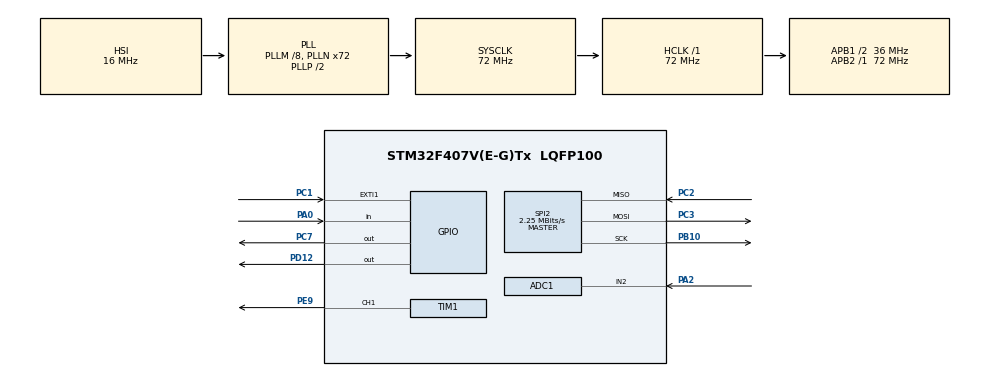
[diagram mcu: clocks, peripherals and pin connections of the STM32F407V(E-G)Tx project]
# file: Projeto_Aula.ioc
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ADC1.Channel-1\#ChannelRegularConversion=ADC_CHANNEL_2
ADC1.ContinuousConvMode=ENABLE
ADC1.NbrOfConversion=1
ADC1.NbrOfConversionFlag=1
ADC1.Rank-1\#ChannelRegularConversion=1
ADC1.SamplingTime-1\#ChannelRegularConversion=ADC_SAMPLETIME_3CYCLES
ADC1.master=1
Mcu.Family=STM32F4
Mcu.Name=STM32F407V(E-G)Tx
Mcu.Package=LQFP100
NVIC.EXTI1_IRQn=true\:0\:0\:false\:false\:true\:true\:true\:true
NVIC.PriorityGroup=NVIC_PRIORITYGROUP_4
PA0-WKUP.Signal=GPIO_Input
PA13.Mode=Serial_Wire
PA13.Signal=SYS_JTMS-SWDIO
PA14.Mode=Serial_Wire
PA14.Signal=SYS_JTCK-SWCLK
PA2.Signal=ADCx_IN2
PB10.Mode=Full_Duplex_Master
PB10.Signal=SPI2_SCK
PC1.GPIO_ModeDefaultEXTI=GPIO_MODE_IT_RISING
PC1.GPIO_PuPd=GPIO_PULLDOWN
PC1.Signal=GPXTI1
PC2.Mode=Full_Duplex_Master
PC2.Signal=SPI2_MISO
PC3.Mode=Full_Duplex_Master
PC3.Signal=SPI2_MOSI
PC7.Signal=GPIO_Output
PD12.Signal=GPIO_Output
PE9.Signal=S_TIM1_CH1
PH0-OSC_IN.Mode=HSE-External-Oscillator
PH0-OSC_IN.Signal=RCC_OSC_IN
PH1-OSC_OUT.Mode=HSE-External-Oscillator
PH1-OSC_OUT.Signal=RCC_OSC_OUT
ProjectManager.HeapSize=0x200
ProjectManager.StackSize=0x400
ProjectManager.TargetToolchain=STM32CubeIDE
RCC.48MHZClocksFreq_Value=36000000
RCC.AHBFreq_Value=72000000
RCC.APB1CLKDivider=RCC_HCLK_DIV2
RCC.APB1Freq_Value=36000000
RCC.APB1TimFreq_Value=72000000
RCC.APB2Freq_Value=72000000
RCC.APB2TimFreq_Value=72000000
RCC.CortexFreq_Value=72000000
RCC.HCLKFreq_Value=72000000
RCC.HSE_VALUE=8000000
RCC.HSI_VALUE=16000000
RCC.LSE_VALUE=32768
RCC.PLLM=8
RCC.PLLN=72
RCC.SYSCLKFreq_VALUE=72000000
RCC.SYSCLKSource=RCC_SYSCLKSOURCE_PLLCLK
RCC.VCOOutputFreq_Value=144000000
SH.ADCx_IN2.0=ADC1_IN2,IN2
SH.S_TIM1_CH1.0=TIM1_CH1,PWM Generation1 CH1
SPI2.BaudRatePrescaler=SPI_BAUDRATEPRESCALER_16
SPI2.CalculateBaudRate=2.25 MBits/s
SPI2.Direction=SPI_DIRECTION_2LINES
SPI2.Mode=SPI_MODE_MASTER
SPI2.VirtualType=VM_MASTER
TIM1.AutoReloadPreload=TIM_AUTORELOAD_PRELOAD_ENABLE
TIM1.Channel-PWM\ Generation1\ CH1=TIM_CHANNEL_1
TIM1.Period=100
TIM1.Prescaler=719
TIM1.Pulse-PWM\ Generation1\ CH1=80
VP_TIM1_VS_ClockSourceINT.Mode=Internal
board=custom

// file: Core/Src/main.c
/* USER CODE BEGIN Header */
/**
  ******************************************************************************
  * @file           : main.c
  * @brief          : Main program body
  ******************************************************************************
  * @attention
  *
  * Copyright (c) 2024 STMicroelectronics.
  * All rights reserved.
  *
  * This software is licensed under terms that can be found in the LICENSE file
  * in the root directory of this software component.
  * If no LICENSE file comes with this software, it is provided AS-IS.
  *
  ******************************************************************************
  */
/* USER CODE END Header */
#include "main.h"

ADC_HandleTypeDef hadc1;

SPI_HandleTypeDef hspi2;

TIM_HandleTypeDef htim1;

void SystemClock_Config(void);
static void MX_GPIO_Init(void);
static void MX_ADC1_Init(void);
static void MX_TIM1_Init(void);
static void MX_SPI2_Init(void);
/* USER CODE BEGIN PFP */
uint16_t adc_read;
uint8_t *buffer = "SEJAM BEM VINDOS A ENGENHARIA ELETRONICA!";
//uint8_t value = 0b10101010;

/* USER CODE END PFP */

int main(void)
{

  /* MCU Configuration--------------------------------------------------------*/

  /* Reset of all peripherals, Initializes the Flash interface and the Systick. */
  HAL_Init();

  /* Configure the system clock */
  SystemClock_Config();

  /* Initialize all configured peripherals */
  MX_GPIO_Init();
  MX_ADC1_Init();
  MX_TIM1_Init();
  MX_SPI2_Init();
  /* USER CODE BEGIN 2 */
  HAL_TIM_PWM_Start(&htim1, TIM_CHANNEL_1);

  /* USER CODE END 2 */

  /* Infinite loop */
  /* USER CODE BEGIN WHILE */
  while (1)
  {

// GPIO OUTPUT -- EXAMPLE
/*
	  while(1){ // HAL -> HARDWARE ABSTRACTION LAYER
		HAL_GPIO_WritePin(GPIOD, GPIO_PIN_12,1);
		HAL_Delay(1000);
		HAL_GPIO_WritePin(GPIOD, GPIO_PIN_12,0);
		HAL_Delay(1000);
	 }
*/

// GPIO INPUT(POLLING) -- EXAMPLE
/*

	  while(1){
		if(HAL_GPIO_ReadPin(GPIOA, GPIO_PIN_0)){
			HAL_GPIO_WritePin(GPIOD, GPIO_PIN_12,1);
		}else{
			HAL_GPIO_WritePin(GPIOD, GPIO_PIN_12,0);
		}
	 }
*/

// ADC(POLLING) -- EXAMPLE

/*

	  while(1){
		  HAL_ADC_Start(&hadc1);
		  HAL_ADC_PollForConversion(&hadc1, 500);
		  adc_read = HAL_ADC_GetValue(&hadc1);
		  HAL_ADC_Stop(&hadc1);
	 }
*/

// TIMER PWM GENERATION -- EXAMPLE

/*
	  while(1){
		TIM1->CCR1 = 80;
		HAL_Delay(5000);
		TIM1->CCR1 = 40;
		HAL_Delay(5000);
	  }
*/

// SPI PROTOCOL SIGNAL GENERATION -- EXAMPLE

	  while(1){
		  HAL_GPIO_WritePin(GPIOC, GPIO_PIN_7,0);
		  HAL_SPI_Transmit(&hspi2,(uint8_t *)buffer,60, 10);
		  HAL_GPIO_WritePin(GPIOC, GPIO_PIN_7,1);
		  HAL_Delay(1000);
	  }

    /* USER CODE END WHILE */

  }
}

void SystemClock_Config(void)
{
  RCC_OscInitTypeDef RCC_OscInitStruct = {0};
  RCC_ClkInitTypeDef RCC_ClkInitStruct = {0};

  /** Configure the main internal regulator output voltage
  */
  __HAL_RCC_PWR_CLK_ENABLE();
  __HAL_PWR_VOLTAGESCALING_CONFIG(PWR_REGULATOR_VOLTAGE_SCALE1);

  /** Initializes the RCC Oscillators according to the specified parameters
  * in the RCC_OscInitTypeDef structure.
  */
  RCC_OscInitStruct.OscillatorType = RCC_OSCILLATORTYPE_HSI;
  RCC_OscInitStruct.HSIState = RCC_HSI_ON;
  RCC_OscInitStruct.HSICalibrationValue = RCC_HSICALIBRATION_DEFAULT;
  RCC_OscInitStruct.PLL.PLLState = RCC_PLL_ON;
  RCC_OscInitStruct.PLL.PLLSource = RCC_PLLSOURCE_HSI;
  RCC_OscInitStruct.PLL.PLLM = 8;
  RCC_OscInitStruct.PLL.PLLN = 72;
  RCC_OscInitStruct.PLL.PLLP = RCC_PLLP_DIV2;
  RCC_OscInitStruct.PLL.PLLQ = 4;
  if (HAL_RCC_OscConfig(&RCC_OscInitStruct) != HAL_OK)
  {
    Error_Handler();
  }

  /** Initializes the CPU, AHB and APB buses clocks
  */
  RCC_ClkInitStruct.ClockType = RCC_CLOCKTYPE_HCLK|RCC_CLOCKTYPE_SYSCLK
                              |RCC_CLOCKTYPE_PCLK1|RCC_CLOCKTYPE_PCLK2;
  RCC_ClkInitStruct.SYSCLKSource = RCC_SYSCLKSOURCE_PLLCLK;
  RCC_ClkInitStruct.AHBCLKDivider = RCC_SYSCLK_DIV1;
  RCC_ClkInitStruct.APB1CLKDivider = RCC_HCLK_DIV2;
  RCC_ClkInitStruct.APB2CLKDivider = RCC_HCLK_DIV1;

  if (HAL_RCC_ClockConfig(&RCC_ClkInitStruct, FLASH_LATENCY_2) != HAL_OK)
  {
    Error_Handler();
  }
}

static void MX_ADC1_Init(void)
{

  ADC_ChannelConfTypeDef sConfig = {0};

  /** Configure the global features of the ADC (Clock, Resolution, Data Alignment and number of conversion)
  */
  hadc1.Instance = ADC1;
  hadc1.Init.ClockPrescaler = ADC_CLOCK_SYNC_PCLK_DIV2;
  hadc1.Init.Resolution = ADC_RESOLUTION_12B;
  hadc1.Init.ScanConvMode = DISABLE;
  hadc1.Init.ContinuousConvMode = ENABLE;
  hadc1.Init.DiscontinuousConvMode = DISABLE;
  hadc1.Init.ExternalTrigConvEdge = ADC_EXTERNALTRIGCONVEDGE_NONE;
  hadc1.Init.ExternalTrigConv = ADC_SOFTWARE_START;
  hadc1.Init.DataAlign = ADC_DATAALIGN_RIGHT;
  hadc1.Init.NbrOfConversion = 1;
  hadc1.Init.DMAContinuousRequests = DISABLE;
  hadc1.Init.EOCSelection = ADC_EOC_SINGLE_CONV;
  if (HAL_ADC_Init(&hadc1) != HAL_OK)
  {
    Error_Handler();
  }

  /** Configure for the selected ADC regular channel its corresponding rank in the sequencer and its sample time.
  */
  sConfig.Channel = ADC_CHANNEL_2;
  sConfig.Rank = 1;
  sConfig.SamplingTime = ADC_SAMPLETIME_3CYCLES;
  if (HAL_ADC_ConfigChannel(&hadc1, &sConfig) != HAL_OK)
  {
    Error_Handler();
  }

}

static void MX_SPI2_Init(void)
{

  /* SPI2 parameter configuration*/
  hspi2.Instance = SPI2;
  hspi2.Init.Mode = SPI_MODE_MASTER;
  hspi2.Init.Direction = SPI_DIRECTION_2LINES;
  hspi2.Init.DataSize = SPI_DATASIZE_8BIT;
  hspi2.Init.CLKPolarity = SPI_POLARITY_LOW;
  hspi2.Init.CLKPhase = SPI_PHASE_1EDGE;
  hspi2.Init.NSS = SPI_NSS_SOFT;
  hspi2.Init.BaudRatePrescaler = SPI_BAUDRATEPRESCALER_16;
  hspi2.Init.FirstBit = SPI_FIRSTBIT_MSB;
  hspi2.Init.TIMode = SPI_TIMODE_DISABLE;
  hspi2.Init.CRCCalculation = SPI_CRCCALCULATION_DISABLE;
  hspi2.Init.CRCPolynomial = 10;
  if (HAL_SPI_Init(&hspi2) != HAL_OK)
  {
    Error_Handler();
  }

}

static void MX_TIM1_Init(void)
{

  TIM_ClockConfigTypeDef sClockSourceConfig = {0};
  TIM_MasterConfigTypeDef sMasterConfig = {0};
  TIM_OC_InitTypeDef sConfigOC = {0};
  TIM_BreakDeadTimeConfigTypeDef sBreakDeadTimeConfig = {0};

  htim1.Instance = TIM1;
  htim1.Init.Prescaler = 719;
  htim1.Init.CounterMode = TIM_COUNTERMODE_UP;
  htim1.Init.Period = 100;
  htim1.Init.ClockDivision = TIM_CLOCKDIVISION_DIV1;
  htim1.Init.RepetitionCounter = 0;
  htim1.Init.AutoReloadPreload = TIM_AUTORELOAD_PRELOAD_ENABLE;
  if (HAL_TIM_Base_Init(&htim1) != HAL_OK)
  {
    Error_Handler();
  }
  sClockSourceConfig.ClockSource = TIM_CLOCKSOURCE_INTERNAL;
  if (HAL_TIM_ConfigClockSource(&htim1, &sClockSourceConfig) != HAL_OK)
  {
    Error_Handler();
  }
  if (HAL_TIM_PWM_Init(&htim1) != HAL_OK)
  {
    Error_Handler();
  }
  sMasterConfig.MasterOutputTrigger = TIM_TRGO_RESET;
  sMasterConfig.MasterSlaveMode = TIM_MASTERSLAVEMODE_DISABLE;
  if (HAL_TIMEx_MasterConfigSynchronization(&htim1, &sMasterConfig) != HAL_OK)
  {
    Error_Handler();
  }
  sConfigOC.OCMode = TIM_OCMODE_PWM1;
  sConfigOC.Pulse = 80;
  sConfigOC.OCPolarity = TIM_OCPOLARITY_HIGH;
  sConfigOC.OCNPolarity = TIM_OCNPOLARITY_HIGH;
  sConfigOC.OCFastMode = TIM_OCFAST_DISABLE;
  sConfigOC.OCIdleState = TIM_OCIDLESTATE_RESET;
  sConfigOC.OCNIdleState = TIM_OCNIDLESTATE_RESET;
  if (HAL_TIM_PWM_ConfigChannel(&htim1, &sConfigOC, TIM_CHANNEL_1) != HAL_OK)
  {
    Error_Handler();
  }
  sBreakDeadTimeConfig.OffStateRunMode = TIM_OSSR_DISABLE;
  sBreakDeadTimeConfig.OffStateIDLEMode = TIM_OSSI_DISABLE;
  sBreakDeadTimeConfig.LockLevel = TIM_LOCKLEVEL_OFF;
  sBreakDeadTimeConfig.DeadTime = 0;
  sBreakDeadTimeConfig.BreakState = TIM_BREAK_DISABLE;
  sBreakDeadTimeConfig.BreakPolarity = TIM_BREAKPOLARITY_HIGH;
  sBreakDeadTimeConfig.AutomaticOutput = TIM_AUTOMATICOUTPUT_DISABLE;
  if (HAL_TIMEx_ConfigBreakDeadTime(&htim1, &sBreakDeadTimeConfig) != HAL_OK)
  {
    Error_Handler();
  }
  HAL_TIM_MspPostInit(&htim1);

}

static void MX_GPIO_Init(void)
{
  GPIO_InitTypeDef GPIO_InitStruct = {0};

  /* GPIO Ports Clock Enable */
  __HAL_RCC_GPIOH_CLK_ENABLE();
  __HAL_RCC_GPIOC_CLK_ENABLE();
  __HAL_RCC_GPIOA_CLK_ENABLE();
  __HAL_RCC_GPIOE_CLK_ENABLE();
  __HAL_RCC_GPIOB_CLK_ENABLE();
  __HAL_RCC_GPIOD_CLK_ENABLE();

  /*Configure GPIO pin Output Level */
  HAL_GPIO_WritePin(GPIOD, GPIO_PIN_12, GPIO_PIN_RESET);

  /*Configure GPIO pin Output Level */
  HAL_GPIO_WritePin(GPIOC, GPIO_PIN_7, GPIO_PIN_RESET);

  /*Configure GPIO pin : PC1 */
  GPIO_InitStruct.Pin = GPIO_PIN_1;
  GPIO_InitStruct.Mode = GPIO_MODE_IT_RISING;
  GPIO_InitStruct.Pull = GPIO_PULLDOWN;
  HAL_GPIO_Init(GPIOC, &GPIO_InitStruct);

  /*Configure GPIO pin : PA0 */
  GPIO_InitStruct.Pin = GPIO_PIN_0;
  GPIO_InitStruct.Mode = GPIO_MODE_INPUT;
  GPIO_InitStruct.Pull = GPIO_NOPULL;
  HAL_GPIO_Init(GPIOA, &GPIO_InitStruct);

  /*Configure GPIO pin : PD12 */
  GPIO_InitStruct.Pin = GPIO_PIN_12;
  GPIO_InitStruct.Mode = GPIO_MODE_OUTPUT_PP;
  GPIO_InitStruct.Pull = GPIO_NOPULL;
  GPIO_InitStruct.Speed = GPIO_SPEED_FREQ_LOW;
  HAL_GPIO_Init(GPIOD, &GPIO_InitStruct);

  /*Configure GPIO pin : PC7 */
  GPIO_InitStruct.Pin = GPIO_PIN_7;
  GPIO_InitStruct.Mode = GPIO_MODE_OUTPUT_PP;
  GPIO_InitStruct.Pull = GPIO_NOPULL;
  GPIO_InitStruct.Speed = GPIO_SPEED_FREQ_LOW;
  HAL_GPIO_Init(GPIOC, &GPIO_InitStruct);

  /* EXTI interrupt init*/
  HAL_NVIC_SetPriority(EXTI1_IRQn, 0, 0);
  HAL_NVIC_EnableIRQ(EXTI1_IRQn);

}

/* USER CODE BEGIN 4 */
void HAL_GPIO_EXTI_Callback(uint16_t GPIO_Pin)
{
  if(GPIO_Pin == GPIO_PIN_1) {
	  HAL_GPIO_TogglePin(GPIOD, GPIO_PIN_12);
	  for(int i=0; i<10000000;i++);
	  } else {
      __NOP();
  }
}

/* USER CODE END 4 */

void Error_Handler(void)
{
  __disable_irq();
  while (1)
  {
  }
}
